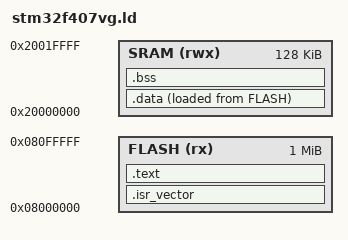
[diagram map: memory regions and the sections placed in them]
ENTRY(Reset_Handler)

MEMORY
{
    FLASH (rx)  : ORIGIN = 0x08000000, LENGTH = 1M
    SRAM  (rwx) : ORIGIN = 0x20000000, LENGTH = 128K
}

_stack_top = ORIGIN(SRAM) + LENGTH(SRAM);

SECTIONS
{
    .isr_vector :
    {
        KEEP(*(.isr_vector))
    } >FLASH

    .text :
    {
        *(.text*)
        *(.rodata*)
    } >FLASH

    _sidata = LOADADDR(.data);

    .data :
    {
        _sdata = .;
        *(.data*)
        _edata = .;
    } >SRAM AT> FLASH

    .bss :
    {
        _sbss = .;
        *(.bss*)
        *(COMMON)
        _ebss = .;
    } >SRAM
}
